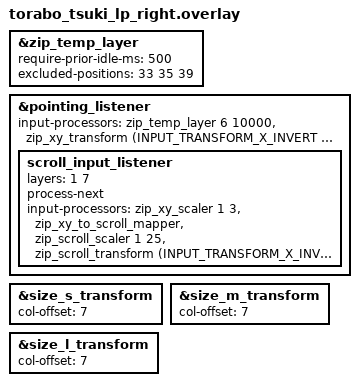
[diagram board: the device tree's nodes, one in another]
#include "torabo_tsuki_lp.dtsi"
#include <input/processors.dtsi>
#include <dt-bindings/zmk/input_transform.h>

&zip_temp_layer {
    require-prior-idle-ms = <500>;
    excluded-positions = <
        33
        35
        39
    >;
};

&pointing_listener {
    input-processors
        = <&zip_temp_layer 6 10000>,
          <&zip_xy_transform (INPUT_TRANSFORM_X_INVERT | INPUT_TRANSFORM_Y_INVERT)>;

    scroll_input_listener {
        layers = <1 7>;
        process-next;
        input-processors
            = <&zip_xy_scaler 1 3>,
              <&zip_xy_to_scroll_mapper>,
              <&zip_scroll_scaler 1 25>,
              <&zip_scroll_transform (INPUT_TRANSFORM_X_INVERT)>;
    };
};

&size_s_transform {
    col-offset = <7>;
};

&size_m_transform {
    col-offset = <7>;
};

&size_l_transform {
    col-offset = <7>;
};
